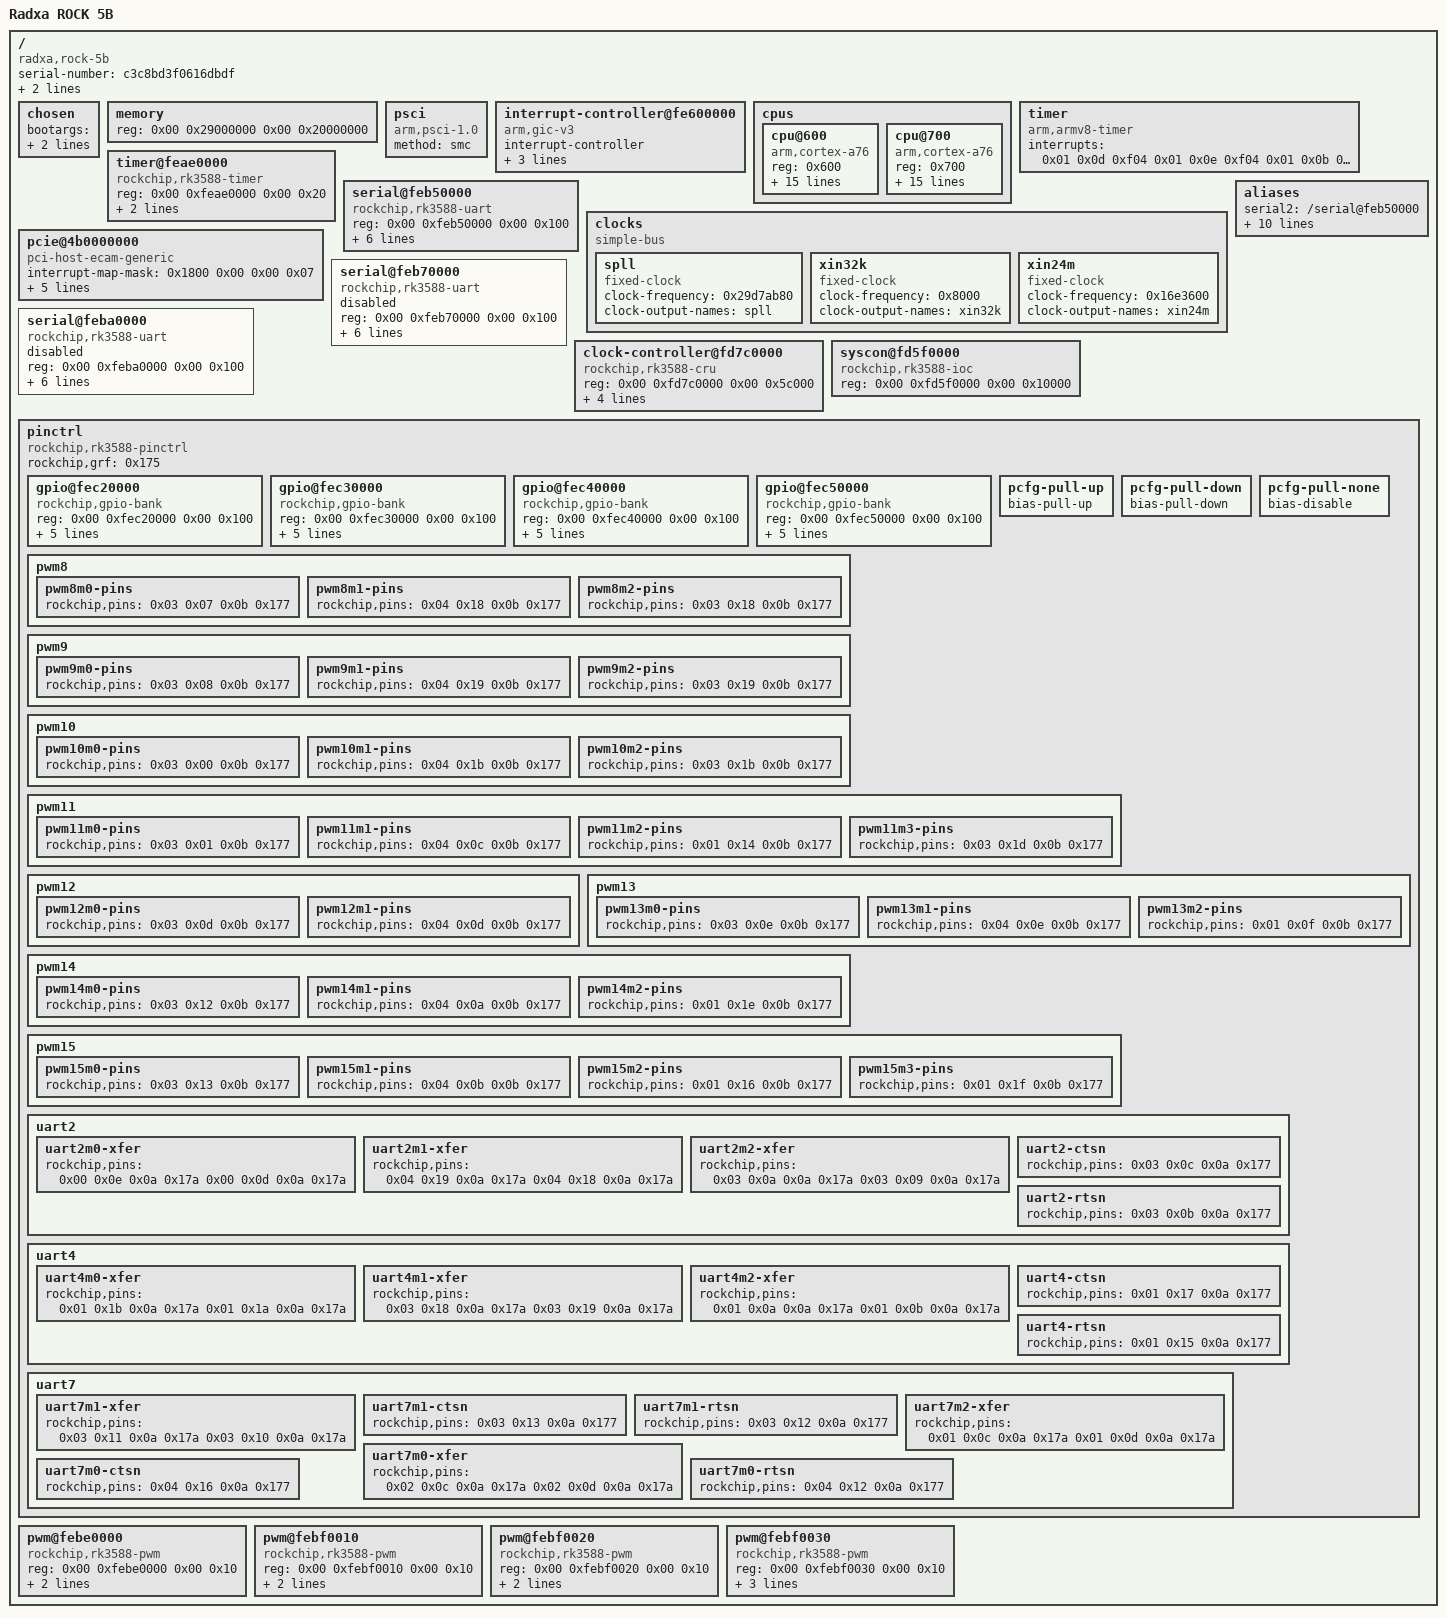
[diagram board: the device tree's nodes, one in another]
/dts-v1/;

/ {
	serial-number = "c3c8bd3f0616dbdf";
	compatible = "radxa,rock-5b\0rockchip,rk3588";
	interrupt-parent = <0x01>;
	#address-cells = <0x02>;
	#size-cells = <0x02>;
	model = "Radxa ROCK 5B";

	chosen {
		bootargs = "earlycon=uart8250,mmio32,0xfeb50000 console=uart2 pic.gicv3_eoimode=1";
		stdout-path = "/serial@feb50000";
	};

	memory {
		reg = <0x00 0x29000000 0x00 0x20000000>;
		device_type = "memory";
	};

	psci {
		compatible = "arm,psci-1.0";
		method = "smc";
	};

	interrupt-controller@fe600000 {
		compatible = "arm,gic-v3";
		#interrupt-cells = <0x03>;
		#address-cells = <0x02>;
		#size-cells = <0x02>;
		ranges;
		interrupt-controller;
		reg = <0x00 0xfe600000 0x00 0x10000 0x00 0xfe680000 0x00 0x100000>;
		interrupts = <0x01 0x09 0x04>;
		phandle = <0x01>;
	};

	cpus {
		#address-cells = <0x01>;
		#size-cells = <0x00>;

		cpu@600 {
			device_type = "cpu";
			compatible = "arm,cortex-a76";
			reg = <0x600>;
			enable-method = "psci";
			capacity-dmips-mhz = <0x400>;
			clocks = <0x0e 0x03>;
			operating-points-v2 = <0x1a>;
			cpu-idle-states = <0x10>;
			i-cache-size = <0x10000>;
			i-cache-line-size = <0x40>;
			i-cache-sets = <0x100>;
			d-cache-size = <0x10000>;
			d-cache-line-size = <0x40>;
			d-cache-sets = <0x100>;
			next-level-cache = <0x1b>;
			#cooling-cells = <0x02>;
			dynamic-power-coefficient = <0x12c>;
			cpu-supply = <0x1c>;
			mem-supply = <0x1c>;
			phandle = <0x0c>;
		};

		cpu@700 {
			device_type = "cpu";
			compatible = "arm,cortex-a76";
			reg = <0x700>;
			enable-method = "psci";
			capacity-dmips-mhz = <0x400>;
			clocks = <0x0e 0x03>;
			operating-points-v2 = <0x1a>;
			cpu-idle-states = <0x10>;
			i-cache-size = <0x10000>;
			i-cache-line-size = <0x40>;
			i-cache-sets = <0x100>;
			d-cache-size = <0x10000>;
			d-cache-line-size = <0x40>;
			d-cache-sets = <0x100>;
			next-level-cache = <0x1d>;
			#cooling-cells = <0x02>;
			dynamic-power-coefficient = <0x12c>;
			cpu-supply = <0x1c>;
			mem-supply = <0x1c>;
			phandle = <0x0d>;
		};
	};

	timer {
		compatible = "arm,armv8-timer";
		interrupts = <0x01 0x0d 0xf04 0x01 0x0e 0xf04 0x01 0x0b 0xf04 0x01 0x0a 0xf04>;
	};

	timer@feae0000 {
		compatible = "rockchip,rk3588-timer\0rockchip,rk3288-timer";
		reg = <0x00 0xfeae0000 0x00 0x20>;
		interrupts = <0x00 0x121 0x04>;
		clocks = <0x02 0x5c 0x02 0x5f>;
		clock-names = "pclk\0timer";
		phandle = <0x270>;
		status = "okay";
	};

	serial@feb50000 {
		compatible = "rockchip,rk3588-uart\0snps,dw-apb-uart";
		reg = <0x00 0xfeb50000 0x00 0x100>;
		interrupts = <0x00 0x14d 0x04>;
		clocks = <0x02 0xbb 0x02 0xac>;
		clock-names = "baudclk\0apb_pclk";
		reg-shift = <0x02>;
		reg-io-width = <0x04>;
		dmas = <0x62 0x0a 0x62 0x0b>;
		pinctrl-names = "default";
		pinctrl-0 = <0x3ff>;
		status = "okay";
		phandle = <0x292>;
	};

	clocks {
		compatible = "simple-bus";
		#address-cells = <0x02>;
		#size-cells = <0x02>;
		ranges;

		spll {
			compatible = "fixed-clock";
			#clock-cells = <0x00>;
			clock-frequency = <0x29d7ab80>;
			clock-output-names = "spll";
			phandle = <0x1bd>;
		};

		xin32k {
			compatible = "fixed-clock";
			#clock-cells = <0x00>;
			clock-frequency = <0x8000>;
			clock-output-names = "xin32k";
			phandle = <0x1be>;
		};

		xin24m {
			compatible = "fixed-clock";
			#clock-cells = <0x00>;
			clock-frequency = <0x16e3600>;
			clock-output-names = "xin24m";
			phandle = <0x1bf>;
		};
	};

	pcie@4b0000000 {
		interrupt-map-mask = <0x1800 0x00 0x00 0x07>;
		interrupt-map = <0x00 0x00 0x00 0x01 0x01 0x00 0x00 0x00 0x3f 0x04 0x00 0x00 0x00 0x02 0x01 0x00 0x00 0x00 0x40 0x04 0x00 0x00 0x00 0x03 0x01 0x00 0x00 0x00 0x41 0x04 0x00 0x00 0x00 0x04 0x01 0x00 0x00 0x00 0x42 0x04 0x800 0x00 0x00 0x01 0x01 0x00 0x00 0x00 0x40 0x04 0x800 0x00 0x00 0x02 0x01 0x00 0x00 0x00 0x41 0x04 0x800 0x00 0x00 0x03 0x01 0x00 0x00 0x00 0x42 0x04 0x800 0x00 0x00 0x04 0x01 0x00 0x00 0x00 0x3f 0x04 0x1000 0x00 0x00 0x01 0x01 0x00 0x00 0x00 0x41 0x04 0x1000 0x00 0x00 0x02 0x01 0x00 0x00 0x00 0x42 0x04 0x1000 0x00 0x00 0x03 0x01 0x00 0x00 0x00 0x3f 0x04 0x1000 0x00 0x00 0x04 0x01 0x00 0x00 0x00 0x40 0x04 0x1800 0x00 0x00 0x01 0x01 0x00 0x00 0x00 0x42 0x04 0x1800 0x00 0x00 0x02 0x01 0x00 0x00 0x00 0x3f 0x04 0x1800 0x00 0x00 0x03 0x01 0x00 0x00 0x00 0x40 0x04 0x1800 0x00 0x00 0x04 0x01 0x00 0x00 0x00 0x41 0x04>;
		#interrupt-cells = <0x01>;
		ranges = <0x3000000 0x04 0xc0000000 0x04 0xc0000000 0x00 0x100000>;
		reg = <0x04 0xb0000000 0x00 0x800000>;
		bus-range = <0x00 0x00>;
		linux,pci-domain = <0x00>;
		#size-cells = <0x02>;
		#address-cells = <0x03>;
		device_type = "pci";
		compatible = "pci-host-ecam-generic";
		status = "okay";
	};

	aliases {
		serial2 = "/serial@feb50000";
		serial4 = "/serial@feb70000";
		serial7 = "/serial@feba0000";
		gpio1 = "/pinctrl/gpio@fec20000";
		gpio2 = "/pinctrl/gpio@fec30000";
		gpio3 = "/pinctrl/gpio@fec40000";
		gpio4 = "/pinctrl/gpio@fec50000";
		pwm8 = "/pwm@febe0000";
		pwm13 = "/pwm@febf0010";
		pwm14 = "/pwm@febf0020";
		pwm15 = "/pwm@febf0030";
	};

	serial@feb70000 {
		compatible = "rockchip,rk3588-uart\0snps,dw-apb-uart";
		reg = <0x00 0xfeb70000 0x00 0x100>;
		interrupts = <0x00 0x14f 0x04>;
		clocks = <0x02 0xc3 0x02 0xae>;
		clock-names = "baudclk\0apb_pclk";
		reg-shift = <0x02>;
		reg-io-width = <0x04>;
		dmas = <0xd3 0x09 0xd3 0x0a>;
		pinctrl-names = "default";
		pinctrl-0 = <0x407>;
		status = "disabled";
		phandle = <0x294>;
	};

	serial@feba0000 {
		compatible = "rockchip,rk3588-uart\0snps,dw-apb-uart";
		reg = <0x00 0xfeba0000 0x00 0x100>;
		interrupts = <0x00 0x152 0x04>;
		clocks = <0x02 0xcf 0x02 0xb1>;
		clock-names = "baudclk\0apb_pclk";
		reg-shift = <0x02>;
		reg-io-width = <0x04>;
		dmas = <0xd4 0x07 0xd4 0x08>;
		dma-names = "!tx\0!rx";
		pinctrl-names = "default";
		pinctrl-0 = <0x14f>;
		status = "disabled";
		phandle = <0x297>;
	};

	clock-controller@fd7c0000 {
		compatible = "rockchip,rk3588-cru";
		reg = <0x00 0xfd7c0000 0x00 0x5c000>;
		#clock-cells = <0x01>;
		#reset-cells = <0x01>;
		assigned-clocks = <0x02 0x09 0x02 0x05 0x02 0x08 0x02 0x07 0x02 0xd8 0x02 0xda 0x02 0xd9 0x02 0x10e 0x02 0x10f 0x02 0x110 0x02 0x299 0x02 0x29a 0x02 0x270 0x02 0x7b 0x02 0xec 0x02 0x114>;
		assigned-clock-rates = <0x4190ab00 0x2ee00000 0x32a9f880 0x46cf7100 0x29d7ab80 0x17d78400 0x1dcd6500 0x2faf0800 0x5f5e100 0x17d78400 0x5f5e100 0xbebc200 0x1dcd6500 0x165a0bc0 0x8f0d180 0xbebc200>;
		phandle = <0x02>;
	};

	syscon@fd5f0000 {
		compatible = "rockchip,rk3588-ioc\0syscon";
		reg = <0x00 0xfd5f0000 0x00 0x10000>;
		phandle = <0x175>;
	};

	pinctrl {
		compatible = "rockchip,rk3588-pinctrl";
		rockchip,grf = <0x175>;
		#address-cells = <0x02>;
		#size-cells = <0x02>;
		ranges;
		phandle = <0x176>;

		gpio@fec20000 {
			compatible = "rockchip,gpio-bank";
			reg = <0x00 0xfec20000 0x00 0x100>;
			interrupts = <0x00 0x116 0x04>;
			clocks = <0x02 0x7d 0x02 0x7e>;
			gpio-controller;
			#gpio-cells = <0x02>;
			gpio-ranges = <0x176 0x00 0x20 0x20>;
			interrupt-controller;
			#interrupt-cells = <0x02>;
			phandle = <0x12b>;
		};

		gpio@fec30000 {
			compatible = "rockchip,gpio-bank";
			reg = <0x00 0xfec30000 0x00 0x100>;
			interrupts = <0x00 0x117 0x04>;
			clocks = <0x02 0x7f 0x02 0x80>;
			gpio-controller;
			#gpio-cells = <0x02>;
			gpio-ranges = <0x176 0x00 0x40 0x20>;
			interrupt-controller;
			#interrupt-cells = <0x02>;
			phandle = <0xda>;
		};

		gpio@fec40000 {
			compatible = "rockchip,gpio-bank";
			reg = <0x00 0xfec40000 0x00 0x100>;
			interrupts = <0x00 0x118 0x04>;
			clocks = <0x02 0x81 0x02 0x82>;
			gpio-controller;
			#gpio-cells = <0x02>;
			gpio-ranges = <0x176 0x00 0x60 0x20>;
			interrupt-controller;
			#interrupt-cells = <0x02>;
			phandle = <0xf0>;
		};

		gpio@fec50000 {
			compatible = "rockchip,gpio-bank";
			reg = <0x00 0xfec50000 0x00 0x100>;
			interrupts = <0x00 0x119 0x04>;
			clocks = <0x02 0x83 0x02 0x84>;
			gpio-controller;
			#gpio-cells = <0x02>;
			gpio-ranges = <0x176 0x00 0x80 0x20>;
			interrupt-controller;
			#interrupt-cells = <0x02>;
			phandle = <0x12c>;
		};

		pcfg-pull-up {
			bias-pull-up;
			phandle = <0x17a>;
		};

		pcfg-pull-down {
			bias-pull-down;
			phandle = <0x17d>;
		};

		pcfg-pull-none {
			bias-disable;
			phandle = <0x177>;
		};

		pwm8 {

			pwm8m0-pins {
				rockchip,pins = <0x03 0x07 0x0b 0x177>;
				phandle = <0x156>;
			};

			pwm8m1-pins {
				rockchip,pins = <0x04 0x18 0x0b 0x177>;
				phandle = <0x3af>;
			};

			pwm8m2-pins {
				rockchip,pins = <0x03 0x18 0x0b 0x177>;
				phandle = <0x3b0>;
			};
		};

		pwm9 {

			pwm9m0-pins {
				rockchip,pins = <0x03 0x08 0x0b 0x177>;
				phandle = <0x157>;
			};

			pwm9m1-pins {
				rockchip,pins = <0x04 0x19 0x0b 0x177>;
				phandle = <0x3b1>;
			};

			pwm9m2-pins {
				rockchip,pins = <0x03 0x19 0x0b 0x177>;
				phandle = <0x3b2>;
			};
		};

		pwm10 {

			pwm10m0-pins {
				rockchip,pins = <0x03 0x00 0x0b 0x177>;
				phandle = <0x158>;
			};

			pwm10m1-pins {
				rockchip,pins = <0x04 0x1b 0x0b 0x177>;
				phandle = <0x3b3>;
			};

			pwm10m2-pins {
				rockchip,pins = <0x03 0x1b 0x0b 0x177>;
				phandle = <0x3b4>;
			};
		};

		pwm11 {

			pwm11m0-pins {
				rockchip,pins = <0x03 0x01 0x0b 0x177>;
				phandle = <0x159>;
			};

			pwm11m1-pins {
				rockchip,pins = <0x04 0x0c 0x0b 0x177>;
				phandle = <0x3b5>;
			};

			pwm11m2-pins {
				rockchip,pins = <0x01 0x14 0x0b 0x177>;
				phandle = <0x3b6>;
			};

			pwm11m3-pins {
				rockchip,pins = <0x03 0x1d 0x0b 0x177>;
				phandle = <0x3b7>;
			};
		};

		pwm12 {

			pwm12m0-pins {
				rockchip,pins = <0x03 0x0d 0x0b 0x177>;
				phandle = <0x15a>;
			};

			pwm12m1-pins {
				rockchip,pins = <0x04 0x0d 0x0b 0x177>;
				phandle = <0x3b8>;
			};
		};

		pwm13 {

			pwm13m0-pins {
				rockchip,pins = <0x03 0x0e 0x0b 0x177>;
				phandle = <0x15b>;
			};

			pwm13m1-pins {
				rockchip,pins = <0x04 0x0e 0x0b 0x177>;
				phandle = <0x3b9>;
			};

			pwm13m2-pins {
				rockchip,pins = <0x01 0x0f 0x0b 0x177>;
				phandle = <0x3ba>;
			};
		};

		pwm14 {

			pwm14m0-pins {
				rockchip,pins = <0x03 0x12 0x0b 0x177>;
				phandle = <0x15c>;
			};

			pwm14m1-pins {
				rockchip,pins = <0x04 0x0a 0x0b 0x177>;
				phandle = <0x3bb>;
			};

			pwm14m2-pins {
				rockchip,pins = <0x01 0x1e 0x0b 0x177>;
				phandle = <0x3bc>;
			};
		};

		pwm15 {

			pwm15m0-pins {
				rockchip,pins = <0x03 0x13 0x0b 0x177>;
				phandle = <0x15d>;
			};

			pwm15m1-pins {
				rockchip,pins = <0x04 0x0b 0x0b 0x177>;
				phandle = <0x3bd>;
			};

			pwm15m2-pins {
				rockchip,pins = <0x01 0x16 0x0b 0x177>;
				phandle = <0x3be>;
			};

			pwm15m3-pins {
				rockchip,pins = <0x01 0x1f 0x0b 0x177>;
				phandle = <0x3bf>;
			};
		};

		uart2 {

			uart2m0-xfer {
				rockchip,pins = <0x00 0x0e 0x0a 0x17a 0x00 0x0d 0x0a 0x17a>;
				phandle = <0x1a8>;
			};

			uart2m1-xfer {
				rockchip,pins = <0x04 0x19 0x0a 0x17a 0x04 0x18 0x0a 0x17a>;
				phandle = <0x149>;
			};

			uart2m2-xfer {
				rockchip,pins = <0x03 0x0a 0x0a 0x17a 0x03 0x09 0x0a 0x17a>;
				phandle = <0x3ff>;
			};

			uart2-ctsn {
				rockchip,pins = <0x03 0x0c 0x0a 0x177>;
				phandle = <0x400>;
			};

			uart2-rtsn {
				rockchip,pins = <0x03 0x0b 0x0a 0x177>;
				phandle = <0x401>;
			};
		};

		uart4 {

			uart4m0-xfer {
				rockchip,pins = <0x01 0x1b 0x0a 0x17a 0x01 0x1a 0x0a 0x17a>;
				phandle = <0x406>;
			};

			uart4m1-xfer {
				rockchip,pins = <0x03 0x18 0x0a 0x17a 0x03 0x19 0x0a 0x17a>;
				phandle = <0x14b>;
			};

			uart4m2-xfer {
				rockchip,pins = <0x01 0x0a 0x0a 0x17a 0x01 0x0b 0x0a 0x17a>;
				phandle = <0x407>;
			};

			uart4-ctsn {
				rockchip,pins = <0x01 0x17 0x0a 0x177>;
				phandle = <0x408>;
			};

			uart4-rtsn {
				rockchip,pins = <0x01 0x15 0x0a 0x177>;
				phandle = <0x409>;
			};
		};

		uart7 {

			uart7m1-xfer {
				rockchip,pins = <0x03 0x11 0x0a 0x17a 0x03 0x10 0x0a 0x17a>;
				phandle = <0x14f>;
			};

			uart7m1-ctsn {
				rockchip,pins = <0x03 0x13 0x0a 0x177>;
				phandle = <0x414>;
			};

			uart7m1-rtsn {
				rockchip,pins = <0x03 0x12 0x0a 0x177>;
				phandle = <0x415>;
			};

			uart7m2-xfer {
				rockchip,pins = <0x01 0x0c 0x0a 0x17a 0x01 0x0d 0x0a 0x17a>;
				phandle = <0x416>;
			};

			uart7m0-xfer {
				rockchip,pins = <0x02 0x0c 0x0a 0x17a 0x02 0x0d 0x0a 0x17a>;
				phandle = <0x417>;
			};

			uart7m0-ctsn {
				rockchip,pins = <0x04 0x16 0x0a 0x177>;
				phandle = <0x418>;
			};

			uart7m0-rtsn {
				rockchip,pins = <0x04 0x12 0x0a 0x177>;
				phandle = <0x419>;
			};
		};
	};

	pwm@febe0000 {
		compatible = "rockchip,rk3588-pwm\0rockchip,rk3328-pwm";
		reg = <0x00 0xfebe0000 0x00 0x10>;
		#pwm-cells = <0x03>;
		pinctrl-names = "active";
		pinctrl-0 = <0x156>;
		clocks = <0x02 0x57 0x02 0x56>;
		clock-names = "pwm\0pclk";
		status = "okay";
		phandle = <0x29e>;
	};

	pwm@febf0010 {
		compatible = "rockchip,rk3588-pwm\0rockchip,rk3328-pwm";
		reg = <0x00 0xfebf0010 0x00 0x10>;
		#pwm-cells = <0x03>;
		pinctrl-names = "active";
		pinctrl-0 = <0x15b>;
		clocks = <0x02 0x5a 0x02 0x59>;
		clock-names = "pwm\0pclk";
		status = "okay";
		phandle = <0x2a3>;
	};

	pwm@febf0020 {
		compatible = "rockchip,rk3588-pwm\0rockchip,rk3328-pwm";
		reg = <0x00 0xfebf0020 0x00 0x10>;
		#pwm-cells = <0x03>;
		pinctrl-names = "active";
		pinctrl-0 = <0x15c>;
		clocks = <0x02 0x5a 0x02 0x59>;
		clock-names = "pwm\0pclk";
		status = "okay";
		phandle = <0x2a4>;
	};

	pwm@febf0030 {
		compatible = "rockchip,rk3588-pwm\0rockchip,rk3328-pwm";
		reg = <0x00 0xfebf0030 0x00 0x10>;
		interrupts = <0x00 0x15e 0x04 0x00 0x15f 0x04>;
		#pwm-cells = <0x03>;
		pinctrl-names = "active";
		pinctrl-0 = <0x15d>;
		clocks = <0x02 0x5a 0x02 0x59>;
		clock-names = "pwm\0pclk";
		status = "okay";
		phandle = <0x2a5>;
	};
};
